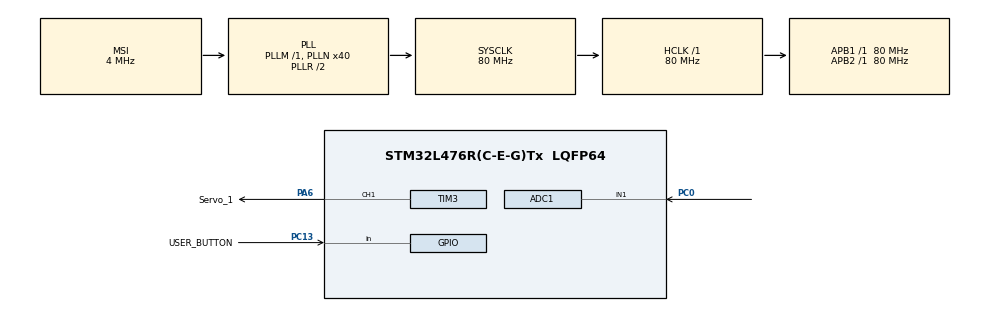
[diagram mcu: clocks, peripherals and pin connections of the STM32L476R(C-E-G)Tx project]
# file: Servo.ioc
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ADC1.Channel-0\#ChannelRegularConversion=ADC_CHANNEL_1
ADC1.NbrOfConversionFlag=1
ADC1.OffsetNumber-0\#ChannelRegularConversion=ADC_OFFSET_NONE
ADC1.Rank-0\#ChannelRegularConversion=1
ADC1.SamplingTime-0\#ChannelRegularConversion=ADC_SAMPLETIME_2CYCLES_5
ADC1.master=1
Mcu.Family=STM32L4
Mcu.Name=STM32L476R(C-E-G)Tx
Mcu.Package=LQFP64
NVIC.ADC1_2_IRQn=true\:0\:0\:false\:true\:true\:1\:true\:true\:true
NVIC.PriorityGroup=NVIC_PRIORITYGROUP_4
PA6.GPIO_Label=Servo_1
PA6.Signal=S_TIM3_CH1
PC0.Signal=ADCx_IN1
PC13.GPIO_Label=USER_BUTTON
PC13.Signal=GPIO_Input
ProjectManager.HeapSize=0x200
ProjectManager.StackSize=0x400
ProjectManager.TargetToolchain=STM32CubeIDE
RCC.ADCFreq_Value=32000000
RCC.AHBFreq_Value=80000000
RCC.APB1Freq_Value=80000000
RCC.APB1TimFreq_Value=80000000
RCC.APB2Freq_Value=80000000
RCC.APB2TimFreq_Value=80000000
RCC.CortexFreq_Value=80000000
RCC.HCLKFreq_Value=80000000
RCC.HSE_VALUE=8000000
RCC.HSI_VALUE=16000000
RCC.LSE_VALUE=32768
RCC.MSI_VALUE=4000000
RCC.PLLN=40
RCC.PLLSAI1N=16
RCC.SYSCLKFreq_VALUE=80000000
RCC.SYSCLKSource=RCC_SYSCLKSOURCE_PLLCLK
RCC.USBFreq_Value=32000000
RCC.VCOOutputFreq_Value=160000000
SH.ADCx_IN1.0=ADC1_IN1,IN1-Single-Ended
SH.S_TIM3_CH1.0=TIM3_CH1,PWM Generation1 CH1
TIM3.AutoReloadPreload=TIM_AUTORELOAD_PRELOAD_ENABLE
TIM3.Channel-PWM\ Generation1\ CH1=TIM_CHANNEL_1
TIM3.Prescaler=79
VP_TIM3_VS_ClockSourceINT.Mode=Internal
board=custom

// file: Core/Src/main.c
/* USER CODE BEGIN Header */
/**
  ******************************************************************************
  * @file           : main.c
  * @brief          : Main program body
  ******************************************************************************
  * @attention
  *
  * Copyright (c) 2024 STMicroelectronics.
  * All rights reserved.
  *
  * This software is licensed under terms that can be found in the LICENSE file
  * in the root directory of this software component.
  * If no LICENSE file comes with this software, it is provided AS-IS.
  *
  ******************************************************************************
  */
/* USER CODE END Header */
#include "main.h"
#include "adc.h"
#include "tim.h"
#include "gpio.h"

/* USER CODE BEGIN Includes */
#include "ServoLib.h"
/* USER CODE END Includes */

/* USER CODE BEGIN PTD */
volatile uint32_t valueADC =0;
void HAL_ADC_ConvCpltCallback(ADC_HandleTypeDef *hadc);
/* USER CODE END PTD */

void SystemClock_Config(void);
static void MX_NVIC_Init(void);

int main(void)
{

  /* MCU Configuration--------------------------------------------------------*/

  /* Reset of all peripherals, Initializes the Flash interface and the Systick. */
  HAL_Init();

  /* Configure the system clock */
  SystemClock_Config();

  /* Initialize all configured peripherals */
  MX_GPIO_Init();
  MX_TIM3_Init();
  MX_ADC1_Init();

  /* Initialize interrupts */
  MX_NVIC_Init();
  /* USER CODE BEGIN 2 */
HAL_TIM_PWM_Start(&htim3,TIM_CHANNEL_1);

servoSetAngle(0, &htim3, TIM_CHANNEL_1);
HAL_ADC_Start_IT(&hadc1);
HAL_Delay(1000);

  /* USER CODE END 2 */

  /* Infinite loop */
  /* USER CODE BEGIN WHILE */
  while (1)
  {

	  servoSetAngle(ADC_TO_ANGLE(valueADC), &htim3, TIM_CHANNEL_1);
	  HAL_ADC_Start_IT(&hadc1);

    /* USER CODE END WHILE */

  }
}

void SystemClock_Config(void)
{
  RCC_OscInitTypeDef RCC_OscInitStruct = {0};
  RCC_ClkInitTypeDef RCC_ClkInitStruct = {0};

  /** Configure the main internal regulator output voltage
  */
  if (HAL_PWREx_ControlVoltageScaling(PWR_REGULATOR_VOLTAGE_SCALE1) != HAL_OK)
  {
    Error_Handler();
  }

  /** Initializes the RCC Oscillators according to the specified parameters
  * in the RCC_OscInitTypeDef structure.
  */
  RCC_OscInitStruct.OscillatorType = RCC_OSCILLATORTYPE_MSI;
  RCC_OscInitStruct.MSIState = RCC_MSI_ON;
  RCC_OscInitStruct.MSICalibrationValue = 0;
  RCC_OscInitStruct.MSIClockRange = RCC_MSIRANGE_6;
  RCC_OscInitStruct.PLL.PLLState = RCC_PLL_ON;
  RCC_OscInitStruct.PLL.PLLSource = RCC_PLLSOURCE_MSI;
  RCC_OscInitStruct.PLL.PLLM = 1;
  RCC_OscInitStruct.PLL.PLLN = 40;
  RCC_OscInitStruct.PLL.PLLP = RCC_PLLP_DIV7;
  RCC_OscInitStruct.PLL.PLLQ = RCC_PLLQ_DIV2;
  RCC_OscInitStruct.PLL.PLLR = RCC_PLLR_DIV2;
  if (HAL_RCC_OscConfig(&RCC_OscInitStruct) != HAL_OK)
  {
    Error_Handler();
  }

  /** Initializes the CPU, AHB and APB buses clocks
  */
  RCC_ClkInitStruct.ClockType = RCC_CLOCKTYPE_HCLK|RCC_CLOCKTYPE_SYSCLK
                              |RCC_CLOCKTYPE_PCLK1|RCC_CLOCKTYPE_PCLK2;
  RCC_ClkInitStruct.SYSCLKSource = RCC_SYSCLKSOURCE_PLLCLK;
  RCC_ClkInitStruct.AHBCLKDivider = RCC_SYSCLK_DIV1;
  RCC_ClkInitStruct.APB1CLKDivider = RCC_HCLK_DIV1;
  RCC_ClkInitStruct.APB2CLKDivider = RCC_HCLK_DIV1;

  if (HAL_RCC_ClockConfig(&RCC_ClkInitStruct, FLASH_LATENCY_4) != HAL_OK)
  {
    Error_Handler();
  }
}

/**
  * @brief NVIC Configuration.
  * @retval None
  */
static void MX_NVIC_Init(void)
{
  /* ADC1_2_IRQn interrupt configuration */
  HAL_NVIC_SetPriority(ADC1_2_IRQn, 0, 0);
  HAL_NVIC_EnableIRQ(ADC1_2_IRQn);
}

/* USER CODE BEGIN 4 */
void HAL_ADC_ConvCpltCallback(ADC_HandleTypeDef *hadc)
{
    if (hadc == &hadc1)
    {

    	valueADC = HAL_ADC_GetValue(hadc);

    }
}

/* USER CODE END 4 */

void Error_Handler(void)
{
  __disable_irq();
  while (1)
  {
  }
}
